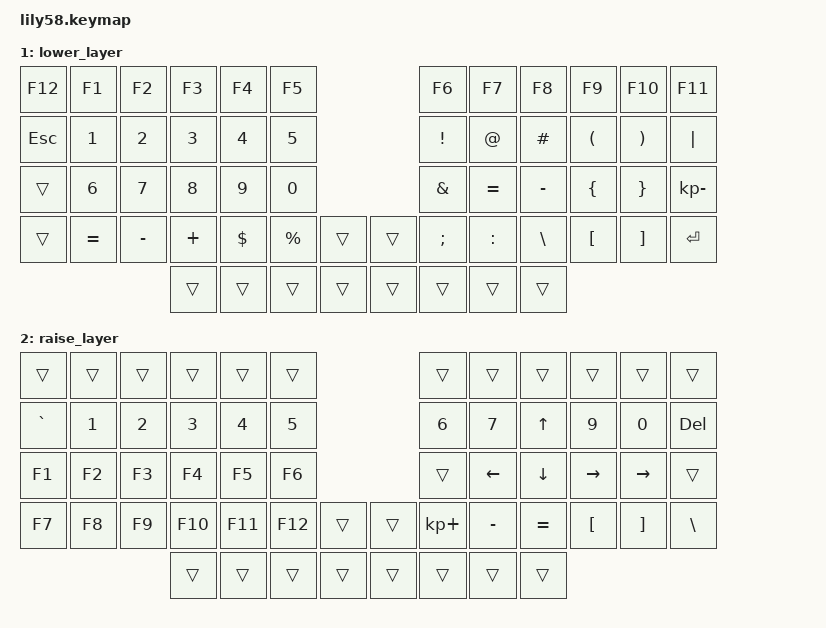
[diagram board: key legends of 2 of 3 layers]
/*
 * Copyright (c) 2020 The ZMK Contributors
 *
 * SPDX-License-Identifier: MIT
 */

#include <behaviors.dtsi>
#include <dt-bindings/zmk/keys.h>
#include <dt-bindings/zmk/bt.h>
#include <dt-bindings/zmk/ext_power.h>

/ {
    keymap {
        compatible = "zmk,keymap";

        default_layer {
// ------------------------------------------------------------------------------------------------------------
// |   `   |  1  |  2  |  3   |   4   |  5   |                   |  6   |  7    |  8    |  9   |   0   |     -     |
// |  ESC  |  Q  |  W  |  E   |   R   |  T   |                   |  Y   |  U    |  I    |  O   |   P   |    BKSP   |
// |  TAB  |  A  |  S  |  D   |   F   |  G   |                   |  H   |  J    |  K    |  L   |   ;   |     '     |
// | SHIFT |  Z  |  X  |  C   |   V   |  B   |   "["  |  |  "]"  |  N   |  M    |  ,    |  .   |   /   | SHFT(RET) |
//                     | ALT  | LCTRL | LOWER|  SPACE |  | SPACE | RAISE| RCTRL |  GUI  |
            bindings = <
&kp GRAVE &kp N1 &kp N2 &kp N3   &kp N4    &kp N5                      &kp N6 &kp N7    &kp N8    &kp N9  &kp N0   &kp MINUS
&kp ESC   &kp Q  &kp W  &kp E    &kp R     &kp T                       &kp Y  &kp U     &kp I     &kp O   &kp P    &kp BSPC
&kp TAB   &kp A  &kp S  &kp D    &kp F     &kp G                       &kp H  &kp J     &kp K     &kp L   &kp SEMI &kp SQT
&kp LSHFT &kp Z  &kp X  &kp C    &kp V     &kp B  &kp LBKT   &kp RBKT  &kp N  &kp M     &kp COMMA &kp DOT &kp FSLH &kp RSHFT RET
                        &kp LALT &kp LCTRL &mo 1  &kp SPACE  &kp SPACE &mo 2  &kp RCTRL &kp RGUI
            >;

            sensor-bindings = <&inc_dec_kp C_VOL_UP C_VOL_DN>;
        };

        lower_layer {
// ------------------------------------------------------------------------------------------------------------
// |  F12   |  F1 |  F2 |  F3  |  F4  |  F5  |                   |  F6  |  F7   |  F8   |  F9  |  F10  |  F11  |
// |  ESC   |  1  |  2  |  3   |  4   |  5   |                   |  !   |  @    |  #    |  (   |   )   |   |   |
// |        |  6  |  7  |  8   |  9   |  0   |                   |  &   |  =    |  -    |  {   |   }   |   -   |
// |        |  =  |  -  |  +   |  $   |  %   |        |  |       |  ;   |  :    |  \    |  [   |   ]   |  RET  |
//                      |      |      |      |        |  |       |      |       |       |
            bindings = <
&kp F12    &kp F1    &kp F2    &kp F3   &kp F4   &kp F5                   &kp F6   &kp F7    &kp F8    &kp F9   &kp F10  &kp F11
&kp ESC    &kp N1    &kp N2    &kp N3   &kp N4   &kp N5                   &kp EXCL &kp AT    &kp HASH  &kp LPAR &kp RPAR &kp PIPE
&trans     &kp N6    &kp N7    &kp N8   &kp N9   &kp N0                   &kp AMPS &kp EQUAL &kp MINUS &kp LBRC &kp RBRC &kp KP_MINUS
&trans     &kp EQUAL &kp MINUS &kp PLUS &kp DLLR &kp PRCNT &trans  &trans &kp SEMI &kp COLON &kp BSLH  &kp LBKT &kp RBKT &kp RET
                               &trans   &trans   &trans    &trans  &trans &trans   &trans    &trans
            >;

            sensor-bindings = <&inc_dec_kp C_VOL_UP C_VOL_DN>;
        };

        raise_layer {
// ------------------------------------------------------------------------------------------------------------
// |       |     |     |      |      |      |                   |      |      |       |       |       |       |
// |   `   |  1  |  2  |  3   |  4   |  5   |                   |  6   |   7  |   UP  |  9    |   0   |  DEL  |
// |   F1  |  F2 |  F3 |  F4  |  F5  |  F6  |                   |      | LEFT |  DOWN | RIGHT |  ->   |       |
// |   F7  |  F8 |  F9 |  F10 |  F11 |  F12 |        |  |       |  +   |   -  |   =   |  [    |   ]   |   \   |
//                     |      |      |      |        |  |       |      |      |       |
            bindings = <
&trans    &trans &trans &trans  &trans  &trans                       &trans      &trans    &trans    &trans    &trans    &trans
&kp GRAVE &kp N1 &kp N2 &kp N3  &kp N4  &kp N5                       &kp N6      &kp N7    &kp UP    &kp N9    &kp N0    &kp DEL
&kp F1    &kp F2 &kp F3 &kp F4  &kp F5  &kp F6                       &trans      &kp LEFT  &kp DOWN  &kp RIGHT &kp RIGHT &trans
&kp F7    &kp F8 &kp F9 &kp F10 &kp F11 &kp F12   &trans   &trans    &kp KP_PLUS &kp MINUS &kp EQUAL &kp LBKT  &kp RBKT  &kp BSLH
                        &trans  &trans  &trans    &trans   &trans    &trans      &trans    &trans
            >;

            sensor-bindings = <&inc_dec_kp C_VOL_UP C_VOL_DN>;
        };
    };
};
